# DISPC_WB register map
Vendor: Texas Instruments
Peripheral module from a debugger description file (folder TDA3x).
Registers are 32-bit, access per field, reset 0x0 unless marked. A register's access mark holds for its fields unless they carry their own. Offsets are as the file gives them; lines under a group give offsets from that group; [hi:lo] are bit positions; {n}, {i} and the like mark numbered series; 'fields as' and 'values as' point back to an identical list; <NAME> marks a mode.

## DISPC_WB
0x00 DISPC_WB_ACCUH_j_0 — The register configures the resize accumulator init values for horizontal up/down-sampling of the wirte-back window It is used for ARGB and Y setting. Shadow register.
  [23:0] HORIZONTALACCU rw — Horizontal initialization accu signed value.
0x04 DISPC_WB_ACCUH_j_1 — The register configures the resize accumulator init values for horizontal up/down-sampling of the wirte-back window It is used for ARGB and Y setting. Shadow register.
  fields as DISPC_WB_ACCUH_j_0
0x08 DISPC_WB_ACCUH2_j_0 — The register configures the resize accumulator init value for horizontal up/down-sampling of the write-back window It is used for Cb and Cr setting. It is used only when the pixel format at the input of the filter is one of the YUV formats. If the pixel format at the input of the filter is ARGB (all ARGB, RGB, RGBA are converted to ARGB32-8888 by the color space conversion before going to the filter is the color space conversion is done before the filter). When the register is not used by the HW, any value can be used for the bit-fields. Shadow register.
  [23:0] HORIZONTALACCU rw — Horizontal initialization accu signed value
0x0C DISPC_WB_ACCUH2_j_1 — The register configures the resize accumulator init value for horizontal up/down-sampling of the write-back window It is used for Cb and Cr setting. It is used only when the pixel format at the input of the filter is one of the YUV formats. If the pixel format at the input of the filter is ARGB (all ARGB, RGB, RGBA are converted to ARGB32-8888 by the color space conversion before going to the filter is the color space conversion is done before the filter). When the register is not used by the HW, any value can be used for the bit-fields. Shadow register.
  fields as DISPC_WB_ACCUH2_j_0
0x10 DISPC_WB_ACCUV_j_0 — The register configures the resize accumulator init value for vertical up/down-sampling of the wirte-back window It is used for ARGB and Y setting. Shadow register.
  [23:0] VERTICALACCU rw — Vertical initialization accu signed value.
0x14 DISPC_WB_ACCUV_j_1 — The register configures the resize accumulator init value for vertical up/down-sampling of the wirte-back window It is used for ARGB and Y setting. Shadow register.
  [23:0] VERTICALACCU rw — Vertical initialization accu signed value.
0x18 DISPC_WB_ACCUV2_j_0 — The register configures the resize accumulator init value for vertical up/down-sampling of the write-back window It is used for Cb and Cr setting. It is used only when the pixel format at the input of the filter is one of the YUV formats. If the pixel format at the input of the filter is ARGB (all ARGB, RGB, RGBA are converted to ARGB32-8888 by the color space conversion before going to the filter is the color space conversion is done before the filter). When the register is not used by the HW, any value can be used for the bit-fields. Shadow register.
  [23:0] VERTICALACCU rw — Vertical initialization accu signed value.
0x1C DISPC_WB_ACCUV2_j_1 — The register configures the resize accumulator init value for vertical up/down-sampling of the write-back window It is used for Cb and Cr setting. It is used only when the pixel format at the input of the filter is one of the YUV formats. If the pixel format at the input of the filter is ARGB (all ARGB, RGB, RGBA are converted to ARGB32-8888 by the color space conversion before going to the filter is the color space conversion is done before the filter). When the register is not used by the HW, any value can be used for the bit-fields. Shadow register.
  [23:0] VERTICALACCU rw — Vertical initialization accu signed value.
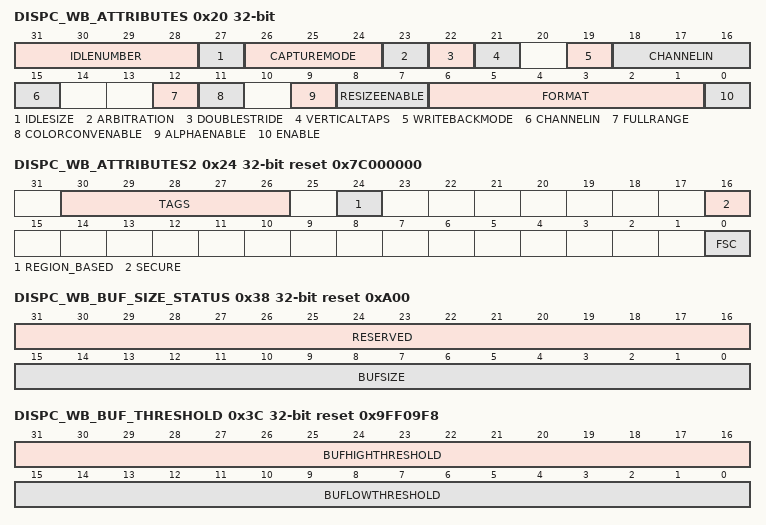
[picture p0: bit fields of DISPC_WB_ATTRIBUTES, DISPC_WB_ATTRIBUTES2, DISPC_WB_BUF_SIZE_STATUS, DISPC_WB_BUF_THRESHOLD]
0x20 DISPC_WB_ATTRIBUTES — The register configures the attributes of the viwrite back pipeline. Shadow register.
  [31:28] IDLENUMBER rw — Determines the number of idles between requests on the L3 interconnect. It is only used when the write-back pipeline does data transfer from memory to memory. When the output of an overlay is stored in memory through the write-back pipeline in capture mode, the bit-field IDLENUMBER is ignored since a timing generator is used to time the transfer. The number of IDLE cycles is IDLENUMBER (from 0 to 15) if IDLESIZE=0. The number of IDLE cycles is IDLENUMBERx8 (from 0 to 120) if IDLESIZE=1 and BURSTSIZE=2. The number of IDLE cycles is IDLENUMBERx4 (from 0 to 60) if IDLESIZE=1 and BURSTSIZE=1. The number of IDLE cycles is IDLENUMBERx2 (from 0 to 30) if IDLESIZE=1 and BURSTSIZE=0.
  [27] IDLESIZE rw — Determines if the IDLENUMBER corresponds to a number of bursts or singles.
    0=IDLESINGLE (The number of idles between requests is defined by IDLENUMBER as number of cycles.); 1=IDLEBURST (The number of idles between requests is defined by IDLENUMBER multiplied by burst size as number of cycles.)
  [26:24] CAPTUREMODE rw — Defines the frame rate capture.
    6=ONLY1_6 (Only one out of six frames is captured. The first one is captured then the second one is skipped and so on.); 1=ONLY1 (Only one frame is captured.); 7=ONLY1_7 (Only one out of seven frames is captured. The first one is captured then the second one is skipped and so on.); 0=ALL (All frames are captures until the write-back channel is disabled or there is no more data generated by the overlay or the pipeline attached to the write-back channel.); 2=ONLY1_2 (Only one out of two frames is captured. The first one is captured then the second one is skipped and so on.); 4=ONLY1_4 (Only one out of four frames is captured. The first one is captured then the second one is skipped and so on.); 5=ONLY1_5 (Only one out of five frames is captured. The first one is captured then the second one is skipped and so on.); 3=ONLY1_3 (Only one out of three frames is captured. The first one is captured then the second one is skipped and so on.)
  [23] ARBITRATION rw — Determines the priority of the write-back pipeline. The write-back pipeline is one of the high priority pipeline. The arbitration gives always the priority first to the high priority pipelines using round-robin between them. When there is only normal priority pipelines sending requests, the round-robin applies between them.
    0=NORMALPRIO (The write-back pipeline is one of the normal priority pipeline.); 1=HIGHPRIO (The write-back pipeline is one of the high priority pipeline.)
  [22] DOUBLESTRIDE rw — Determines if the stride for CbCr buffer is the 1x or 2x of the Y buffer stride. It is only used in case of YUV420 and 2D access
    0=INITIAL (The CbCr stride value is equal to the Y stride.); 1=DOUBLE (The CbCr stride value is double to the Y stride.)
  [21] VERTICALTAPS rw — Video Vertical Resize Tap Number
    0=TAPS3 (3 taps are used for the vertical filtering logic. The 2 other taps are not used.); 1=TAPS5 (5 taps are used for the vertical filtering logic.)
  [19] WRITEBACKMODE rw — When connected to the overlay output of a channel the write back can operate as a simple transfer from memory to memory (composition engine) or as a capture channel.
    0=CAPTURE (Capture mode (default mode); 1=MEM2MEM (Memory to memory mode)
  [18:15] CHANNELIN rw — WB Channel In configuration wr: immediate
    0=VP1SEL (OVR1 (VP1)); 1=VP1SEL (OVR2); 4=GFX1SEL; 7=VID1SEL; 8=VID2SEL
  [12] FULLRANGE rw — Color Space Conversion full range setting.
    0=LIMRANGE (Limited range selected: 16 subtracted from Y before color space conversion); 1=FULLRANGE (Full range selected: Y is not modified before the color space conversion)
  [11] COLORCONVENABLE rw — Enable the color space conversion. The HW does not enable/disable the conversion based on the pixel format. The bit-field shall be reset when the format is not YUV.
    0=COLSPCDIS (Disable Color Space Conversion RGB to YUV); 1=COLSPCENB (Enable Color Space Conversion RGB to YUV)
  [9] ALPHAENABLE rw — Premultiplied alpha enable
    0=DISABLE (disabled.Disabled. This bit also disable the logic present in the associated channel out that compute the alpha component sent to the WB pipe); 1=ENABLE (enabled.)
  [8:7] RESIZEENABLE rw
    0=RESIZEPROC (Disable the resize processing); 1=HRESIZE (Enable the horizontal resize processing); 3=HVRESIZE (Enable both horizontal and vertical resize processing); 2=VRESIZE (Enable the vertical resize processing)
  [6:1] FORMAT rw — Write-back Format. It defines the pixel format when storing the write-back picture into memory.
    9=RGBA32_8888; 8=ABGR32_8888; 5=ARGB16_1555; 2=RGBA16_4444; 11=RGB24P_888 (RGB24-888 (24-bit container)); 4=BGR16_565; 1=ABGR16_4444; 63=UYVY (UYVY 4:2:2 co-sited); 40=XBGR32_8888; 0=ARGB16_4444; 62=YUV2 (YUV2 4:2:2 co-sited); 37=XRGB16_1555; 61=NV12 (NV12/NV21 4:2:0 2 buffers (Y + UV)); 32=XRGB16_4444 (xRGB12-4444); 3=RGB16_565; 23=BGR565A8; 48=XRGB64_16161616; 17=RGBA64_16161616; 6=ABGR16_1555; 49=RGBX64_16161616; 10=BGRA32_8888; 38=XBGR16_1555; 16=ARGB64_16161616; 33=XBGR16_4444; 22=RGB565A8; 42=BGRX32_8888; 7=ARGB32_8888; 39=XRGB32_8888 (xRGB32-8888 (32-bit container)); 41=RGBX32_8888 (RGBx32-8888 (24-bit RGB aligned on MSB of the 32-bit container)); 34=RGBX16_4444
  [0] ENABLE rw — Write-back Enable. wr: immediate
    0=WBDIS (Write-back disabled); 1=WBENB (Write-back enabled)
0x24 DISPC_WB_ATTRIBUTES2 reset 0x7C000000 — The register set the WB pipe. Shadow register.
  [30:26] TAGS rw — Number of OCP TAGS to be used for the pipeline (from 1 to 32)
  [24] REGION_BASED rw — Enable region-based mechanism for WBPipe
    0=DISABLE; 1=ENABLE
  [16] SECURE rw — OCP requests corresponds to pipeline data are secure/unsecure. The bit-field can be modified only by secure transaction using MReqSecure qualifier.
  [0] FSC rw — Field Sequential Color generation : R,G, and B buffers are generated from RGB buffer.
    0=DISABLE; 1=ENABLE
0x28 DISPC_WB_BA_j_0 rw — The register configures the base address of the WB buffer (DISPC_WB_BA__0 DISPC_WB_BA__1 for ping-pong mechanism with external trigger, based on the field polarity otherwise only DISPC_WB_BA__0 is used). Shadow register.
  [31:0] BA — Write-back base address Base address of the WB buffer (aligned on pixel size boundary except in case of RGB24 packed format, 4-pixel alignment is required; in case of YUV422, 2-pixel alignment is required, and YUV420, byte alignment is supported)). It case of YUV 4:2:0 format, it indicates the base address of the Y buffer. When the TILER is addressed, the bits: [28:27] = 0x0 for 8-bit tiled [28:27] = 0x1 for 16-bit tiled [28:27] = 0x2 for 32-bit tiled [28:27] = 0x3 for page mode [31:29] = 0x0 for 0-degree view [31:29] = 0x1 for 180-degree view + mirroring [31:29] = 0x2 for 0-degree view + mirroring [31:29] = 0x3 for 180-degree view [31:29] = 0x4 for 270-degree view + mirroring [31:29] = 0x5 for 270-degree view [31:29] = 0x6 for 90-degree view [31:29] = 0x7 for 90-degree view + mirroring Otherwise the bits indicated the corresponding bit address to access the SDRAM.
0x2C DISPC_WB_BA_j_1 rw — The register configures the base address of the WB buffer (DISPC_WB_BA__0 DISPC_WB_BA__1 for ping-pong mechanism with external trigger, based on the field polarity otherwise only DISPC_WB_BA__0 is used). Shadow register.
  fields as DISPC_WB_BA_j_0
0x30 DISPC_WB_BA_UV_j_0 rw — The register configures the base address of the UV buffer for the write-back pipeline. (DISPC_WB_BA_UV_0 and DISPC_WB_BA_UV_1 for ping-pong mechanism with external trigger, based on the field polarity, otherwise only DISPC_WB_BA_UV_0 is used)). The register is also used to configure the RGB plane BA for RGB565A8 format. Shadow register.
  [31:0] BA — Video base address alinged on 16-bit boundary Base address of the UV video buffer used only in case of YUV420-NV12 When the TILER is addressed, the bits: [28:27] = 0x0 for 8-bit tiled [28:27] = 0x1 for 16-bit tiled [28:27] = 0x2 for 32-bit tiled [28:27] = 0x3 for page mode [31:29] = 0x0 for 0-degree view [31:29] = 0x1 for 180-degree view + mirroring [31:29] = 0x2 for 0-degree view + mirroring [31:29] = 0x3 for 180-degree view [31:29] = 0x4 for 270-degree view + mirroring [31:29] = 0x5 for 270-degree view [31:29] = 0x6 for 90-degree view [31:29] = 0x7 for 90-degree view + mirroring Otherwise the bits indicated the corresponding bit address to access the SDRAM.
0x34 DISPC_WB_BA_UV_j_1 rw — The register configures the base address of the UV buffer for the write-back pipeline. (DISPC_WB_BA_UV_0 and DISPC_WB_BA_UV_1 for ping-pong mechanism with external trigger, based on the field polarity, otherwise only DISPC_WB_BA_UV_0 is used)). The register is also used to configure the RGB plane BA for RGB565A8 format. Shadow register.
  fields as DISPC_WB_BA_UV_j_0
0x38 DISPC_WB_BUF_SIZE_STATUS ro reset 0xA00 — The register defines the DMA buufer size for the write back pipeline.
  [31:16] RESERVED — Write 0's for future compatibility. Reads return 0
  [15:0] BUFSIZE — DMA buffer Size in number of 128-bits.
0x3C DISPC_WB_BUF_THRESHOLD rw reset 0x9FF09F8 — The register configures the DMA buffer associated with the write-back pipeline. Shadow register.
  [31:16] BUFHIGHTHRESHOLD — DMA buffer High Threshold Number of 128-bits defining the threshold value.
  [15:0] BUFLOWTHRESHOLD — DMA buffer High Threshold Number of 128-bits defining the threshold value.
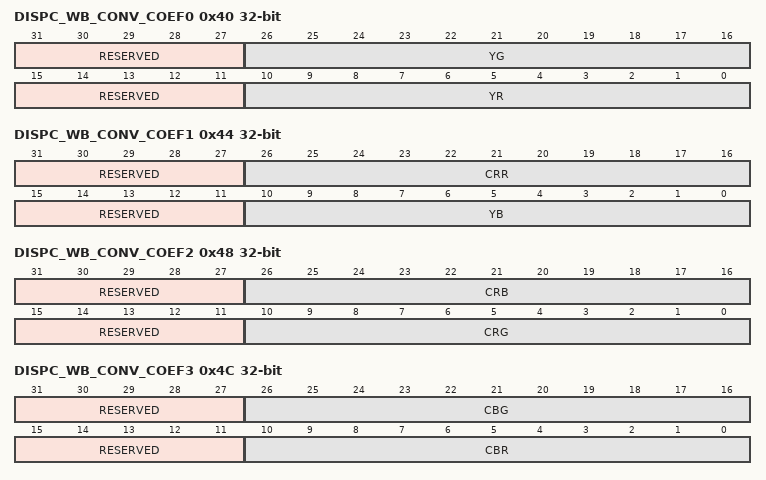
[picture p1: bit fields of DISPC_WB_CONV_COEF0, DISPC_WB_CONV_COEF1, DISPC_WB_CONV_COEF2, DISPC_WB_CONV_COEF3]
0x40 DISPC_WB_CONV_COEF0 — The register configures the color space conversion matrix coefficients for the write back pipeline (YUV444 to RGB24) Shadow register.
  [31:27] RESERVED ro — Write 0's for future compatibility. Reads return 0
  [26:16] YG rw — YG Coefficient Encoded signed value (from -1024 to 1023).
  [15:11] RESERVED ro — Write 0's for future compatibility. Reads return 0
  [10:0] YR rw — YR Coefficient Encoded signed value (from -1024 to 1023).
0x44 DISPC_WB_CONV_COEF1 — The register configures the color space conversion matrix coefficients for the write back pipeline. Shadow register.
  [31:27] RESERVED ro — Write 0's for future compatibility. Reads return 0
  [26:16] CRR rw — CrR Coefficient Encoded signed value (from -1024 to 1023).
  [15:11] RESERVED ro — Write 0's for future compatibility. Reads return 0
  [10:0] YB rw — YB Coefficient Encoded signed value (from -1024 to 1023).
0x48 DISPC_WB_CONV_COEF2 — The register configures the color space conversion matrix coefficients for the write back pipeline. Shadow register.
  [31:27] RESERVED ro — Write 0's for future compatibility. Reads return 0
  [26:16] CRB rw — CrB Coefficient Encoded signed value (from -1024 to 1023).
  [15:11] RESERVED ro — Write 0's for future compatibility. Reads return 0
  [10:0] CRG rw — CrG Coefficient Encoded signed value (from -1024 to 1023).
0x4C DISPC_WB_CONV_COEF3 — The register configures the color space conversion matrix coefficients for the write back pipeline. Shadow register.
  [31:27] RESERVED ro — Write 0's for future compatibility. Reads return 0
  [26:16] CBG rw — CbG coefficient Encoded signed value (from -1024 to 1023).
  [15:11] RESERVED ro — Write 0's for future compatibility. Reads return 0
  [10:0] CBR rw — CbR coefficient Encoded signed value (from -1024 to 1023).
0x50 DISPC_WB_CONV_COEF4 — The register configures the color space conversion matrix coefficients for the write back pipeline. Shadow register.
  [10:0] CBB rw — CbB Coefficient Encoded signed value (from -1024 to 1023).
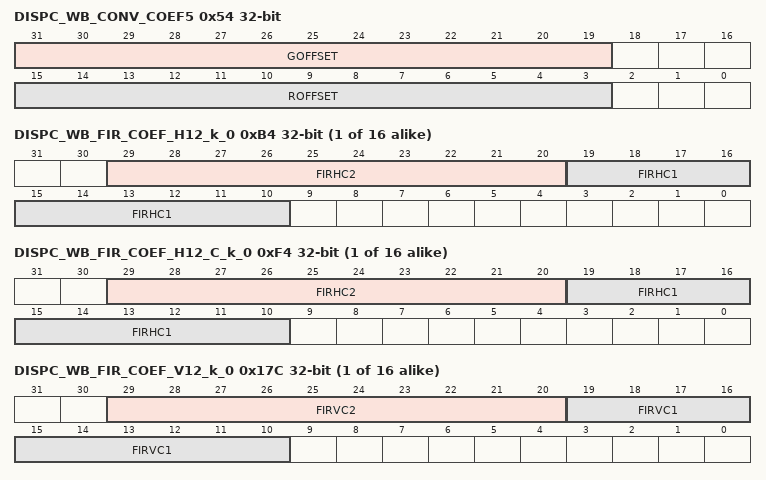
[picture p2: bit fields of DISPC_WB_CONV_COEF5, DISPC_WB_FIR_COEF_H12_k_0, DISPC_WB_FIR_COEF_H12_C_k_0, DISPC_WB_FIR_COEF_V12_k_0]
0x54 DISPC_WB_CONV_COEF5 — The register configures the color space conversion matrix coefficients for the write-back pipeline. Shadow register.
  [31:19] GOFFSET rw — G offset Encoded signed value (from -4096 to 4095).
  [15:3] ROFFSET rw — R offset Encoded signed value (from -4096 to 4095).
0x58 DISPC_WB_CONV_COEF6 — The register configures the color space conversion matrix coefficients for the write-back pipeline. Shadow register.
  [15:3] BOFFSET rw — B offset Encoded signed value (from -4096 to 4095).
0x5C DISPC_WB_FIRH reset 0x200000 — The register configures the resize factor for horizontal up/down-sampling of the write-back window. It is used for ARGB and Y setting. Shadow register.
  [23:0] FIRHINC rw — Horizontal increment of the up/down-sampling filter. The value 0 is invalid.
0x60 DISPC_WB_FIRH2 reset 0x200000 — The register configures the resize factor for horizontal up/down-sampling of the wirte-back window. It is used for Crb and Cr setting. It is used only when the pixel format at the input of the filter is one of the YUV formats. If the pixel format at the input of the filter is ARGB (all ARGB, RGB, RGBA are converted to ARGB32-8888 by the color space conversion before going to the filter is the color space conversion is done before the filter). When the register is not used by the HW, any value can be used for the bit-fields. Shadow register.
  [23:0] FIRHINC rw — Horizontal increment of the up/down-sampling filter for Cb and Cr. The value 0 is invalid.
0x64 DISPC_WB_FIRV reset 0x200000 — The register configures the resize factor for vertical up/down-sampling of the write-back window It is used for ARGB and Y setting. Shadow register.
  [23:0] FIRVINC rw — Vertical increment of the up/down-sampling filter. The value 0 is invalid.
0x68 DISPC_WB_FIRV2 reset 0x200000 — The register configures the resize factor for vertical up/down-sampling of the wirte-back window. It is used for Crb and Cr setting. It is used only when the pixel format at the input of the filter is one of the YUV formats. If the pixel format at the input of the filter is ARGB (all ARGB, RGB, RGBA are converted to ARGB32-8888 by the color space conversion before going to the filter is the color space conversion is done before the filter). When the register is not used by the HW, any value can be used for the bit-fields. Shadow register.
  [23:0] FIRVINC rw — Vertical increment of the up/down-sampling filter for Cb and Cr. The value 0 is invalid.
{0x6C+4i} DISPC_WB_FIR_COEF_H0_i_{i} (i=0..8) — The bank of registers configure the up/down-scaling coefficients for the horizontal resize of the video picture associated with the write back pipeline for the phases from 0 to 15. It is used for ARGB and Y setting. Shadow register.
  [9:0] FIRHC0 rw — Unsigned coefficient C0 for the horizontal up/down-scaling with the phase n
{0x90+4i} DISPC_WB_FIR_COEF_H0_C_i_{i} (i=0..8) — The bank of registers configure the up/down-scaling coefficients for the horizontal resize of the video picture associated with the write back pipeline for the phases from 0 to 15. It is used for Crb and Cr setting. It is used only when the pixel format at the input of the filter is one of the YUV formats. If the pixel format at the input of the filter is ARGB (all ARGB, RGB, RGBA are converted to ARGB32-8888 by the color space conversion before going to the filter is the color space conversion is done before the filter). When the register is not used by the HW, any value can be used for the bit-fields. Shadow register.
  fields as DISPC_WB_FIR_COEF_H0_i_0
{0xB4+4i} DISPC_WB_FIR_COEF_H12_k_{i} (i=0..15) — The bank of registers configure the up/down-scaling coefficients for the horizontal resize of the video picture associated with the write back pipeline for the phases from 0 to 15. It is used for ARGB and Y setting. Shadow register.
  [29:20] FIRHC2 rw — Signed coefficient C2 for the horizontal up/down-scaling with the phase n
  [19:10] FIRHC1 rw — Signed coefficient C1 for the horizontal up/down-scaling with the phase n
{0xF4+4i} DISPC_WB_FIR_COEF_H12_C_k_{i} (i=0..15) — The bank of registers configure the up/down-scaling coefficients for the horizontal resize of the video picture associated with the write back pipeline for the phases from 0 to 15. It is used for Crb and Cr setting. It is used only when the pixel format at the input of the filter is one of the YUV formats. If the pixel format at the input of the filter is ARGB (all ARGB, RGB, RGBA are converted to ARGB32-8888 by the color space conversion before going to the filter is the color space conversion is done before the filter). When the register is not used by the HW, any value can be used for the bit-fields. Shadow register.
  fields as DISPC_WB_FIR_COEF_H12_k_0
{0x134+4i} DISPC_WB_FIR_COEF_V0_i_{i} (i=0..8) — The bank of registers configure the down/up/down-scaling coefficients for the vertical resize of the video picture associated with the write back pipeline for the phases from 0 to 15. It is used for ARGB and Y setting. Shadow register.
  [9:0] FIRVC0 rw — Unsigned coefficient C0 for the vertical up/down-scaling with the phase n
{0x158+4i} DISPC_WB_FIR_COEF_V0_C_i_{i} (i=0..8) — The bank of registers configure the down/up/down-scaling coefficients for the vertical resize of the video picture associated with the write back pipeline for the phases from 0 to 15. It is used for Crb and Cr setting. It is used only when the pixel format at the input of the filter is one of the YUV formats. If the pixel format at the input of the filter is ARGB (all ARGB, RGB, RGBA are converted to ARGB32-8888 by the color space conversion before going to the filter is the color space conversion is done before the filter). When the register is not used by the HW, any value can be used for the bit-fields. Shadow register.
  fields as DISPC_WB_FIR_COEF_V0_i_0
{0x17C+4i} DISPC_WB_FIR_COEF_V12_k_{i} (i=0..15) — The bank of registers configure the down/up/down-scaling coefficients for the vertical resize of the video picture associated with the write back pipeline for the phases from 0 to 15. It is used for ARGB and Y setting. Shadow register.
  [29:20] FIRVC2 rw — Signed coefficient C2 for the vertical up/down-scaling with the phase n
  [19:10] FIRVC1 rw — Signed coefficient C1 for the vertical up/down-scaling with the phase n
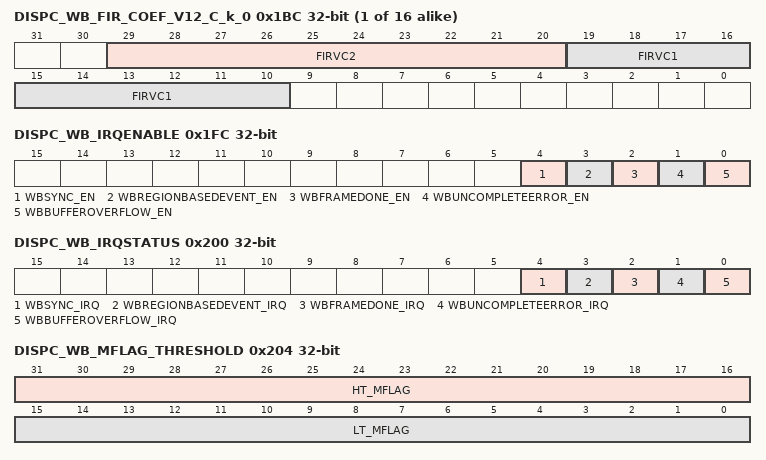
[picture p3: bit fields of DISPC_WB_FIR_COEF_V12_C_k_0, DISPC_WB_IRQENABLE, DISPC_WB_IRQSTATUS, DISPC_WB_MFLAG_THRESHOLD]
{0x1BC+4i} DISPC_WB_FIR_COEF_V12_C_k_{i} (i=0..15) — The bank of registers configure the down/up/down-scaling coefficients for the vertical resize of the video picture associated with the write back pipeline for the phases from 0 to 15. It is used for Crb and Cr setting. It is used only when the pixel format at the input of the filter is one of the YUV formats. If the pixel format at the input of the filter is ARGB (all ARGB, RGB, RGBA are converted to ARGB32-8888 by the color space conversion before going to the filter is the color space conversion is done before the filter). When the register is not used by the HW, any value can be used for the bit-fields. Shadow register.
  fields as DISPC_WB_FIR_COEF_V12_k_0
0x1FC DISPC_WB_IRQENABLE — This register allows to mask/unmask the module internal sources of interrupt, on an event-by-event basis
  [4] WBSYNC_EN rw — Write-back synced (configuration copied from shadow to work)
    0=MASKED (WBBufferOverflow is masked); 1=GENINT (WBBufferOverflow generates an interrupt when it occurs)
  [3] WBREGIONBASEDEVENT_EN rw — For Write-back region-based, event indicating end of current window
    values as WBSYNC_EN
  [2] WBFRAMEDONE_EN rw — Write-back Frame Done.
    values as WBSYNC_EN
  [1] WBUNCOMPLETEERROR_EN rw — The write back buffer has been flushed before been fully drained. Enable
    0=MASKED (Interrupt is masked); 1=GENINT (Interrupt is enabled)
  [0] WBBUFFEROVERFLOW_EN rw — Write-back DMA Buffer Overflow. The DMA buffer is full
    values as WBSYNC_EN
0x200 DISPC_WB_IRQSTATUS — This register regroups all the status of the module internal events that generate an interrupt. Write 1 to a given bit resets this bit
  [4] WBSYNC_IRQ rw — Write-back synced (configuration copied from shadow to work)
    0=FALSE (READS: Event is false. WRITES: Status bit unchanged.); 1=TRUE (READS: Event is true (pending). WRITES: Status bit is reset.)
  [3] WBREGIONBASEDEVENT_IRQ rw — Write-back Frame Done.
    values as WBSYNC_IRQ
  [2] WBFRAMEDONE_IRQ rw — Write-back Frame Done.
    values as WBSYNC_IRQ
  [1] WBUNCOMPLETEERROR_IRQ rw — Write back DMA buffer is flushed before been completely drained.
    0=FALSE (READS: Event is false. WRITES: Status bit unchanged.); 1=TRUE (READS: Event is true (Pending) WRITE: Status bit is reset)
  [0] WBBUFFEROVERFLOW_IRQ rw — Write-back DMA Buffer Overrflow. The DMA buffer is full.
    values as WBSYNC_IRQ
0x204 DISPC_WB_MFLAG_THRESHOLD rw
  [31:16] HT_MFLAG, [15:0] LT_MFLAG
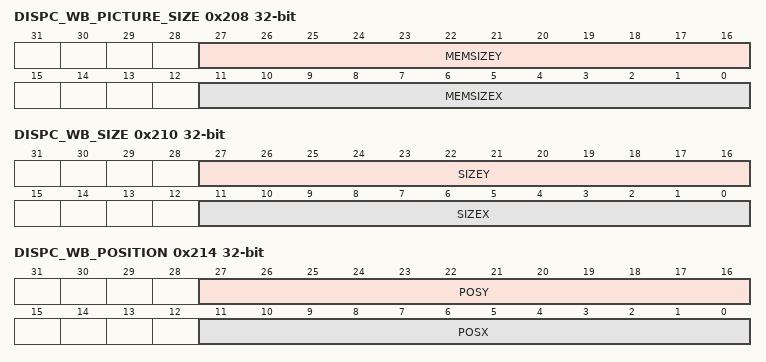
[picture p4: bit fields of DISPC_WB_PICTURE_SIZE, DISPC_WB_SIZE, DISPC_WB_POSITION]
0x208 DISPC_WB_PICTURE_SIZE — The register configures the size of the write-back picture associated with the write back pipeline after up/down-scaling (size of the image stored in DDR memory, generated by WB pipe). Shadow register.
  [27:16] MEMSIZEY rw — Number of lines of the wb picture in memory Encoded value (from 1 to 4096) to specify the number of lines of the picture store in memory (program to value minus one).
  [11:0] MEMSIZEX rw — Number of pixels of the wb picture in memory. Encoded value (from 1 to 4096) to specify the number of pixels of the picture stored in memory (program to value minus one). In case of 32-bit RGB/ARGB/RGBA pixel formats and 2D burst, the maximum width is limited to 2048 pixels.
0x210 DISPC_WB_SIZE — The register configures the size of the output of overlay connected to the write-back pipeline when the overlay output is only used by the write-back pipeline. When the overlay is output on the VP1 output, the size of the frame is defined in the register. Shadow register.
  [27:16] SIZEY rw — Number of lines of the Write-back picture Encoded value (from 1 to 4096) to specify the number of lines of the write-back picture from overlay or pipeline.
  [11:0] SIZEX rw — Number of pixels of the Write-back picture Encoded value (from 1 to 4096) to specify the number of pixels of the write-back picture from overlay or pipeline..
0x214 DISPC_WB_POSITION — The register configures the start position of the window on overlay which wb will capture Shadow register.
  [27:16] POSY rw — Y position of the video window Encoded value (from 0 to 4095) to specify the Y position of the video window #1 .The line at the top has the Y-position 0.
  [11:0] POSX rw — X position of the video window Encoded value (from 0 to 4095) to specify the X position of the video window #1. The first pixel on the left of the display screen has the X-position 0.
0x218 DISPC_WB_REGION_BASED_TOTAL_PICTURE_SIZEY — The register configures the total sizey (total number of lines) of all the windows written back to the memory in Write-Back Region-based mode. Shadow register.
  [11:0] SIZEY rw — Total number of lines of the Write-back picture in Region-based mode Encoded value (from 1 to 4096) to specify the number of lines of the write-back picture from overlay or pipeline.
